# BL602 register map
Vendor: bouffalolab; Series: WiFi BT
Registers are 32-bit, read-write, reset 0x0 unless marked. A register's access mark holds for its fields unless they carry their own. Offsets are from the block's base; [hi:lo] are bit positions; {n}, {i} and the like mark numbered series.

## SF_CTRL — Flash control
Base 0x4000B000
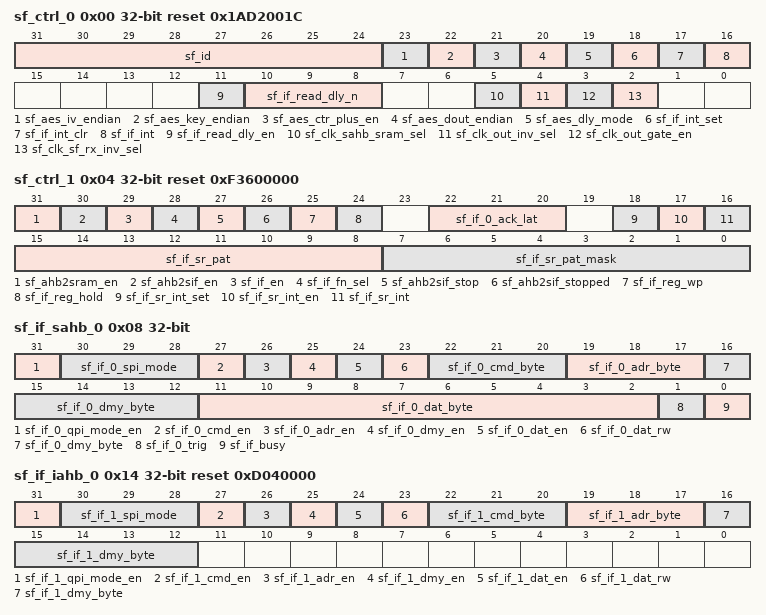
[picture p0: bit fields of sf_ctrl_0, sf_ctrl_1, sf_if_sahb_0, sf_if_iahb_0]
0x00 sf_ctrl_0 reset 0x1AD2001C
  [31:24] sf_id, [23] sf_aes_iv_endian, [22] sf_aes_key_endian, [21] sf_aes_ctr_plus_en, [20] sf_aes_dout_endian, [19] sf_aes_dly_mode, [18] sf_if_int_set, [17] sf_if_int_clr, [16] sf_if_int ro, [11] sf_if_read_dly_en, [10:8] sf_if_read_dly_n, [5] sf_clk_sahb_sram_sel, [4] sf_clk_out_inv_sel, [3] sf_clk_out_gate_en, [2] sf_clk_sf_rx_inv_sel
0x04 sf_ctrl_1 reset 0xF3600000
  [31] sf_ahb2sram_en, [30] sf_ahb2sif_en, [29] sf_if_en, [28] sf_if_fn_sel, [27] sf_ahb2sif_stop, [26] sf_ahb2sif_stopped ro, [25] sf_if_reg_wp, [24] sf_if_reg_hold, [22:20] sf_if_0_ack_lat, [18] sf_if_sr_int_set, [17] sf_if_sr_int_en, [16] sf_if_sr_int ro, [15:8] sf_if_sr_pat, [7:0] sf_if_sr_pat_mask
0x08 sf_if_sahb_0
  [31] sf_if_0_qpi_mode_en, [30:28] sf_if_0_spi_mode, [27] sf_if_0_cmd_en, [26] sf_if_0_adr_en, [25] sf_if_0_dmy_en, [24] sf_if_0_dat_en, [23] sf_if_0_dat_rw, [22:20] sf_if_0_cmd_byte, [19:17] sf_if_0_adr_byte, [16:12] sf_if_0_dmy_byte, [11:2] sf_if_0_dat_byte, [1] sf_if_0_trig, [0] sf_if_busy ro
0x0C sf_if_sahb_1
  [31:0] sf_if_0_cmd_buf_0
0x10 sf_if_sahb_2
  [31:0] sf_if_0_cmd_buf_1
0x14 sf_if_iahb_0 reset 0xD040000
  [31] sf_if_1_qpi_mode_en, [30:28] sf_if_1_spi_mode, [27] sf_if_1_cmd_en, [26] sf_if_1_adr_en, [25] sf_if_1_dmy_en, [24] sf_if_1_dat_en, [23] sf_if_1_dat_rw, [22:20] sf_if_1_cmd_byte, [19:17] sf_if_1_adr_byte, [16:12] sf_if_1_dmy_byte
0x18 sf_if_iahb_1 reset 0x3000000
  [31:0] sf_if_1_cmd_buf_0
0x1C sf_if_iahb_2
  [31:0] sf_if_1_cmd_buf_1
0x20 sf_if_status_0 ro
0x24 sf_if_status_1 ro reset 0x20000000
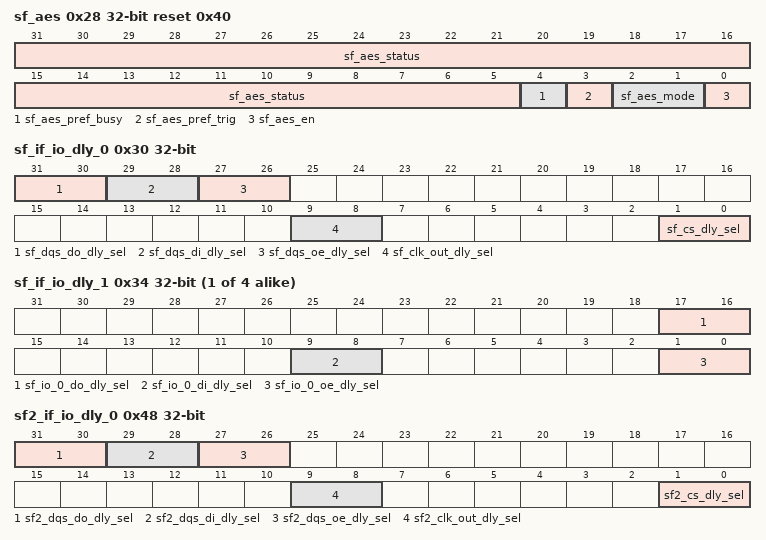
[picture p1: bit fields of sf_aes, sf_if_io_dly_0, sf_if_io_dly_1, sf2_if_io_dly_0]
0x28 sf_aes reset 0x40
  [31:5] sf_aes_status ro, [4] sf_aes_pref_busy ro, [3] sf_aes_pref_trig, [2:1] sf_aes_mode, [0] sf_aes_en
0x2C sf_ahb2sif_status ro reset 0x10000003
0x30 sf_if_io_dly_0
  [31:30] sf_dqs_do_dly_sel, [29:28] sf_dqs_di_dly_sel, [27:26] sf_dqs_oe_dly_sel, [9:8] sf_clk_out_dly_sel, [1:0] sf_cs_dly_sel
{0x30+4i} sf_if_io_dly_{i} (i=1..4)
  [17:16] sf_io_{i-1}_do_dly_sel, [9:8] sf_io_{i-1}_di_dly_sel, [1:0] sf_io_{i-1}_oe_dly_sel
0x44 sf_reserved
0x48 sf2_if_io_dly_0
  [31:30] sf2_dqs_do_dly_sel, [29:28] sf2_dqs_di_dly_sel, [27:26] sf2_dqs_oe_dly_sel, [9:8] sf2_clk_out_dly_sel, [1:0] sf2_cs_dly_sel
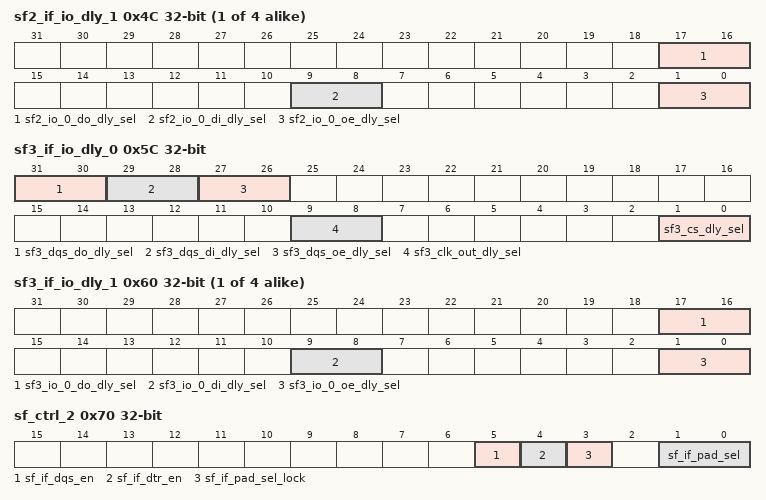
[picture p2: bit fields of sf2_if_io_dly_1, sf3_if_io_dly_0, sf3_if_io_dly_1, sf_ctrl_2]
{0x48+4i} sf2_if_io_dly_{i} (i=1..4)
  [17:16] sf2_io_{i-1}_do_dly_sel, [9:8] sf2_io_{i-1}_di_dly_sel, [1:0] sf2_io_{i-1}_oe_dly_sel
0x5C sf3_if_io_dly_0
  [31:30] sf3_dqs_do_dly_sel, [29:28] sf3_dqs_di_dly_sel, [27:26] sf3_dqs_oe_dly_sel, [9:8] sf3_clk_out_dly_sel, [1:0] sf3_cs_dly_sel
{0x5C+4i} sf3_if_io_dly_{i} (i=1..4)
  [17:16] sf3_io_{i-1}_do_dly_sel, [9:8] sf3_io_{i-1}_di_dly_sel, [1:0] sf3_io_{i-1}_oe_dly_sel
0x70 sf_ctrl_2
  [5] sf_if_dqs_en, [4] sf_if_dtr_en, [3] sf_if_pad_sel_lock, [1:0] sf_if_pad_sel
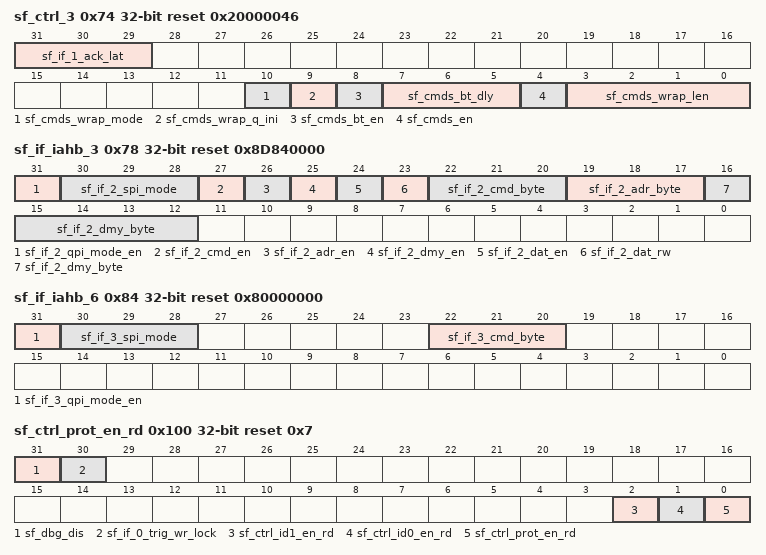
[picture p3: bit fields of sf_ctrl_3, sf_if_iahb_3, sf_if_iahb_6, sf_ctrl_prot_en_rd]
0x74 sf_ctrl_3 reset 0x20000046
  [31:29] sf_if_1_ack_lat, [10] sf_cmds_wrap_mode, [9] sf_cmds_wrap_q_ini, [8] sf_cmds_bt_en, [7:5] sf_cmds_bt_dly, [4] sf_cmds_en, [3:0] sf_cmds_wrap_len
0x78 sf_if_iahb_3 reset 0x8D840000
  [31] sf_if_2_qpi_mode_en, [30:28] sf_if_2_spi_mode, [27] sf_if_2_cmd_en, [26] sf_if_2_adr_en, [25] sf_if_2_dmy_en, [24] sf_if_2_dat_en, [23] sf_if_2_dat_rw, [22:20] sf_if_2_cmd_byte, [19:17] sf_if_2_adr_byte, [16:12] sf_if_2_dmy_byte
0x7C sf_if_iahb_4 reset 0x38000000
  [31:0] sf_if_2_cmd_buf_0
0x80 sf_if_iahb_5
  [31:0] sf_if_2_cmd_buf_1
0x84 sf_if_iahb_6 reset 0x80000000
  [31] sf_if_3_qpi_mode_en, [30:28] sf_if_3_spi_mode, [22:20] sf_if_3_cmd_byte
0x88 sf_if_iahb_7 reset 0xC0000000
  [31:0] sf_if_3_cmd_buf_0
0x100 sf_ctrl_prot_en_rd ro reset 0x7
  [31] sf_dbg_dis, [30] sf_if_0_trig_wr_lock, [2] sf_ctrl_id1_en_rd, [1] sf_ctrl_id0_en_rd, [0] sf_ctrl_prot_en_rd
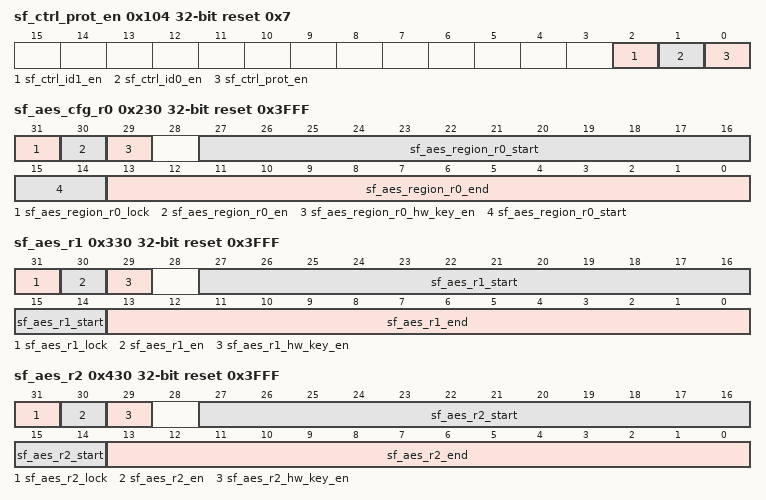
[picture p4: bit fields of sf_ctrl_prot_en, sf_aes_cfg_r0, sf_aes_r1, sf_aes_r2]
0x104 sf_ctrl_prot_en reset 0x7
  [2] sf_ctrl_id1_en, [1] sf_ctrl_id0_en, [0] sf_ctrl_prot_en
{0x200+4i} sf_aes_key_r0_{i} (i=0..7)
{0x220+4i} sf_aes_iv_r0_w{i} (i=0..3)
0x230 sf_aes_cfg_r0 reset 0x3FFF
  [31] sf_aes_region_r0_lock, [30] sf_aes_region_r0_en, [29] sf_aes_region_r0_hw_key_en, [27:14] sf_aes_region_r0_start, [13:0] sf_aes_region_r0_end
{0x300+4i} sf_aes_key_r1_{i} (i=0..7)
{0x320+4i} sf_aes_iv_r1_w{i} (i=0..3)
0x330 sf_aes_r1 reset 0x3FFF
  [31] sf_aes_r1_lock, [30] sf_aes_r1_en, [29] sf_aes_r1_hw_key_en, [27:14] sf_aes_r1_start, [13:0] sf_aes_r1_end
{0x400+4i} sf_aes_key_r2_{i} (i=0..7)
{0x420+4i} sf_aes_iv_r2_w{i} (i=0..3)
0x430 sf_aes_r2 reset 0x3FFF
  [31] sf_aes_r2_lock, [30] sf_aes_r2_en, [29] sf_aes_r2_hw_key_en, [27:14] sf_aes_r2_start, [13:0] sf_aes_r2_end
0x434 sf_id0_offset
  [23:0] sf_id0_offset
0x438 sf_id1_offset
  [23:0] sf_id1_offset
